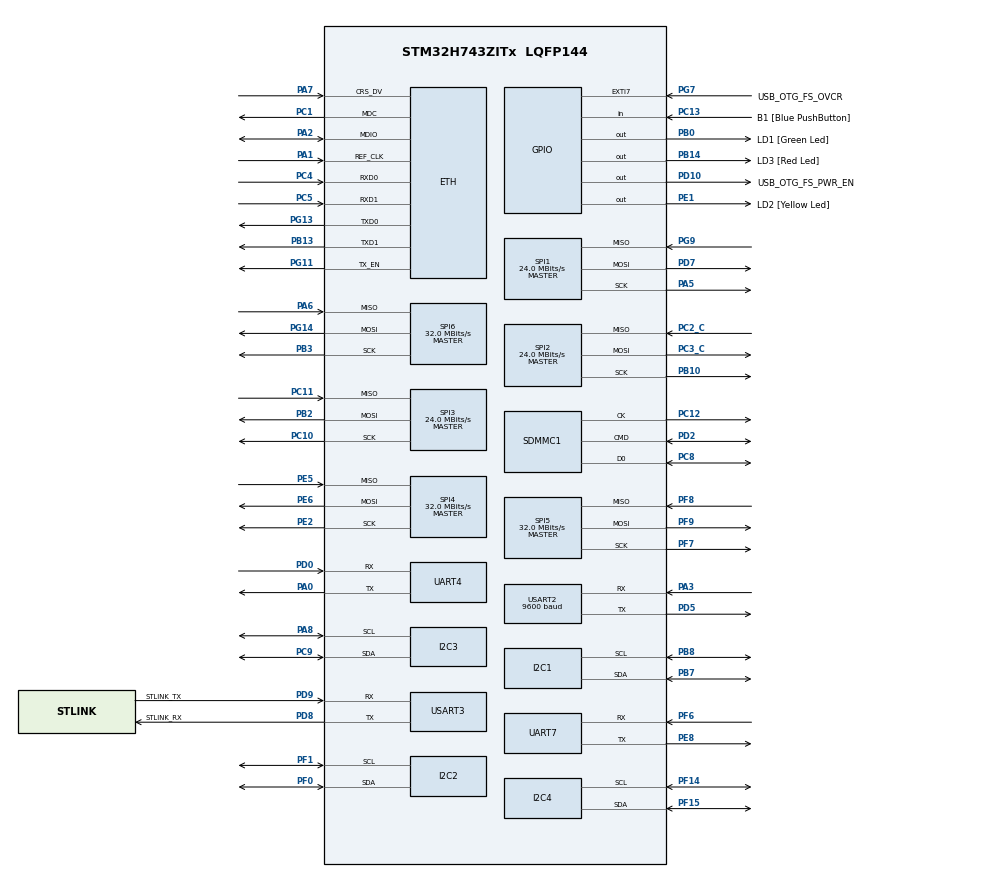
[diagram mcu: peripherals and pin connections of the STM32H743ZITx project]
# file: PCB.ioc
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Dma.Request0=USART2_RX
Dma.USART2_RX.0.Direction=DMA_PERIPH_TO_MEMORY
Dma.USART2_RX.0.EventEnable=DISABLE
Dma.USART2_RX.0.FIFOMode=DMA_FIFOMODE_DISABLE
Dma.USART2_RX.0.Instance=DMA2_Stream0
Dma.USART2_RX.0.MemDataAlignment=DMA_MDATAALIGN_BYTE
Dma.USART2_RX.0.MemInc=DMA_MINC_ENABLE
Dma.USART2_RX.0.Mode=DMA_CIRCULAR
Dma.USART2_RX.0.PeriphDataAlignment=DMA_PDATAALIGN_BYTE
Dma.USART2_RX.0.PeriphInc=DMA_PINC_DISABLE
Dma.USART2_RX.0.Polarity=HAL_DMAMUX_REQ_GEN_RISING
Dma.USART2_RX.0.Priority=DMA_PRIORITY_LOW
Dma.USART2_RX.0.RequestNumber=1
Dma.USART2_RX.0.SignalID=NONE
Dma.USART2_RX.0.SyncEnable=DISABLE
Dma.USART2_RX.0.SyncPolarity=HAL_DMAMUX_SYNC_NO_EVENT
Dma.USART2_RX.0.SyncRequestNumber=1
Dma.USART2_RX.0.SyncSignalID=NONE
ETH.MediaInterface=HAL_ETH_RMII_MODE
Mcu.Family=STM32H7
Mcu.Name=STM32H743ZITx
Mcu.Package=LQFP144
NVIC.DMA2_Stream0_IRQn=true\:0\:0\:false\:false\:true\:false\:true\:true
NVIC.PriorityGroup=NVIC_PRIORITYGROUP_4
NVIC.USART2_IRQn=true\:0\:0\:false\:false\:true\:true\:true\:true
PA0.Mode=Asynchronous
PA0.Signal=UART4_TX
PA1.Mode=RMII
PA1.Signal=ETH_REF_CLK
PA11.Signal=USB_OTG_FS_DM
PA12.Signal=USB_OTG_FS_DP
PA2.Mode=RMII
PA2.Signal=ETH_MDIO
PA3.Mode=Asynchronous
PA3.Signal=USART2_RX
PA5.Mode=Full_Duplex_Master
PA5.Signal=SPI1_SCK
PA6.Mode=Full_Duplex_Master
PA6.Signal=SPI6_MISO
PA7.Mode=RMII
PA7.Signal=ETH_CRS_DV
PA8.Mode=I2C
PA8.Signal=I2C3_SCL
PA9.Signal=I2C3_SMBA
PB0.GPIO_Label=LD1 [Green Led]
PB0.Signal=GPIO_Output
PB10.Mode=Full_Duplex_Master
PB10.Signal=SPI2_SCK
PB13.Mode=RMII
PB13.Signal=ETH_TXD1
PB14.GPIO_Label=LD3 [Red Led]
PB14.Signal=GPIO_Output
PB2.Mode=Full_Duplex_Master
PB2.Signal=SPI3_MOSI
PB3\ (JTDO/TRACESWO).Mode=Full_Duplex_Master
PB3\ (JTDO/TRACESWO).Signal=SPI6_SCK
PB7.Mode=I2C
PB7.Signal=I2C1_SDA
PB8.Mode=I2C
PB8.Signal=I2C1_SCL
PC1.Mode=RMII
PC1.Signal=ETH_MDC
PC10.Mode=Full_Duplex_Master
PC10.Signal=SPI3_SCK
PC11.Mode=Full_Duplex_Master
PC11.Signal=SPI3_MISO
PC12.Mode=SD_1_bit
PC12.Signal=SDMMC1_CK
PC13.GPIO_Label=B1 [Blue PushButton]
PC13.Signal=GPIO_Input
PC14-OSC32_IN\ (OSC32_IN).Mode=LSE-External-Oscillator
PC14-OSC32_IN\ (OSC32_IN).Signal=RCC_OSC32_IN
PC15-OSC32_OUT\ (OSC32_OUT).Mode=LSE-External-Oscillator
PC15-OSC32_OUT\ (OSC32_OUT).Signal=RCC_OSC32_OUT
PC2_C.Mode=Full_Duplex_Master
PC2_C.Signal=SPI2_MISO
PC3_C.Mode=Full_Duplex_Master
PC3_C.Signal=SPI2_MOSI
PC4.Mode=RMII
PC4.Signal=ETH_RXD0
PC5.Mode=RMII
PC5.Signal=ETH_RXD1
PC8.Mode=SD_1_bit
PC8.Signal=SDMMC1_D0
PC9.Mode=I2C
PC9.Signal=I2C3_SDA
PD0.Mode=Asynchronous
PD0.Signal=UART4_RX
PD10.GPIO_Label=USB_OTG_FS_PWR_EN
PD10.Signal=GPIO_Output
PD2.Mode=SD_1_bit
PD2.Signal=SDMMC1_CMD
PD5.Mode=Asynchronous
PD5.Signal=USART2_TX
PD7.Mode=Full_Duplex_Master
PD7.Signal=SPI1_MOSI
PD8.GPIO_Label=STLINK_RX
PD8.Mode=Asynchronous
PD8.Signal=USART3_TX
PD9.GPIO_Label=STLINK_TX
PD9.Mode=Asynchronous
PD9.Signal=USART3_RX
PE1.GPIO_Label=LD2 [Yellow Led]
PE1.Signal=GPIO_Output
PE2.Mode=Full_Duplex_Master
PE2.Signal=SPI4_SCK
PE5.Mode=Full_Duplex_Master
PE5.Signal=SPI4_MISO
PE6.Mode=Full_Duplex_Master
PE6.Signal=SPI4_MOSI
PE8.Mode=Asynchronous
PE8.Signal=UART7_TX
PF0.Mode=I2C
PF0.Signal=I2C2_SDA
PF1.Mode=I2C
PF1.Signal=I2C2_SCL
PF14.Mode=I2C
PF14.Signal=I2C4_SCL
PF15.Mode=I2C
PF15.Signal=I2C4_SDA
PF6.Mode=Asynchronous
PF6.Signal=UART7_RX
PF7.Mode=Full_Duplex_Master
PF7.Signal=SPI5_SCK
PF8.Mode=Full_Duplex_Master
PF8.Signal=SPI5_MISO
PF9.Mode=Full_Duplex_Master
PF9.Signal=SPI5_MOSI
PG11.Mode=RMII
PG11.Signal=ETH_TX_EN
PG13.Mode=RMII
PG13.Signal=ETH_TXD0
PG14.Mode=Full_Duplex_Master
PG14.Signal=SPI6_MOSI
PG7.GPIO_Label=USB_OTG_FS_OVCR
PG7.Signal=GPXTI7
PG9.Mode=Full_Duplex_Master
PG9.Signal=SPI1_MISO
PH0-OSC_IN\ (PH0).Mode=HSE-External-Clock-Source
PH0-OSC_IN\ (PH0).Signal=RCC_OSC_IN
PH1-OSC_OUT\ (PH1).Signal=RCC_OSC_OUT
ProjectManager.HeapSize=0x200
ProjectManager.StackSize=0x400
ProjectManager.TargetToolchain=STM32CubeIDE
RCC.ADCFreq_Value=16125000
RCC.APB1Freq_Value=64000000
RCC.APB2Freq_Value=64000000
RCC.APB3Freq_Value=64000000
RCC.APB4Freq_Value=64000000
RCC.CortexFreq_Value=64000000
RCC.DIVM1=1
RCC.DIVN1=24
RCC.DIVQ1=4
RCC.HCLKFreq_Value=64000000
RCC.HSE_VALUE=8000000
RCC.PLLFRACN=0
RCC.PLLSourceVirtual=RCC_PLLSOURCE_HSE
RCC.PWR_Regulator_Voltage_Scale=PWR_REGULATOR_VOLTAGE_SCALE2
RCC.SYSCLKFreq_VALUE=64000000
RCC.USBFreq_Value=48000000
SPI1.CalculateBaudRate=24.0 MBits/s
SPI1.Direction=SPI_DIRECTION_2LINES
SPI1.Mode=SPI_MODE_MASTER
SPI1.VirtualType=VM_MASTER
SPI2.CalculateBaudRate=24.0 MBits/s
SPI2.Direction=SPI_DIRECTION_2LINES
SPI2.Mode=SPI_MODE_MASTER
SPI2.VirtualType=VM_MASTER
SPI3.CalculateBaudRate=24.0 MBits/s
SPI3.Direction=SPI_DIRECTION_2LINES
SPI3.Mode=SPI_MODE_MASTER
SPI3.VirtualType=VM_MASTER
SPI4.CalculateBaudRate=32.0 MBits/s
SPI4.Direction=SPI_DIRECTION_2LINES
SPI4.Mode=SPI_MODE_MASTER
SPI4.VirtualType=VM_MASTER
SPI5.CalculateBaudRate=32.0 MBits/s
SPI5.Direction=SPI_DIRECTION_2LINES
SPI5.Mode=SPI_MODE_MASTER
SPI5.VirtualType=VM_MASTER
SPI6.CalculateBaudRate=32.0 MBits/s
SPI6.Direction=SPI_DIRECTION_2LINES
SPI6.Mode=SPI_MODE_MASTER
SPI6.VirtualType=VM_MASTER
USART2.BaudRate=9600
USART2.VirtualMode-Asynchronous=VM_ASYNC
USART3.VirtualMode-Asynchronous=VM_ASYNC
board=NUCLEO-H743ZI2

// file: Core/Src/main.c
/* USER CODE BEGIN Header */
/**
  ******************************************************************************
  * @file           : main.c
  * @brief          : Main program body
  ******************************************************************************
  * @attention
  *
  * Copyright (c) 2024 STMicroelectronics.
  * All rights reserved.
  *
  * This software is licensed under terms that can be found in the LICENSE file
  * in the root directory of this software component.
  * If no LICENSE file comes with this software, it is provided AS-IS.
  *
  ******************************************************************************
  */
/* USER CODE END Header */
#include "main.h"
#include "string.h"

/* USER CODE BEGIN Includes */
#include "barometer.h"
#include "gps.h"
/* USER CODE END Includes */

#if defined ( __ICCARM__ ) /*!< IAR Compiler */
#pragma location=0x30000000
ETH_DMADescTypeDef  DMARxDscrTab[ETH_RX_DESC_CNT]; /* Ethernet Rx DMA Descriptors */
#pragma location=0x30000200
ETH_DMADescTypeDef  DMATxDscrTab[ETH_TX_DESC_CNT]; /* Ethernet Tx DMA Descriptors */

#elif defined ( __CC_ARM )  /* MDK ARM Compiler */

__attribute__((at(0x30000000))) ETH_DMADescTypeDef  DMARxDscrTab[ETH_RX_DESC_CNT]; /* Ethernet Rx DMA Descriptors */
__attribute__((at(0x30000200))) ETH_DMADescTypeDef  DMATxDscrTab[ETH_TX_DESC_CNT]; /* Ethernet Tx DMA Descriptors */

#elif defined ( __GNUC__ ) /* GNU Compiler */
ETH_DMADescTypeDef DMARxDscrTab[ETH_RX_DESC_CNT] __attribute__((section(".RxDecripSection"))); /* Ethernet Rx DMA Descriptors */
ETH_DMADescTypeDef DMATxDscrTab[ETH_TX_DESC_CNT] __attribute__((section(".TxDecripSection")));   /* Ethernet Tx DMA Descriptors */

#endif

ETH_TxPacketConfig TxConfig;

ETH_HandleTypeDef heth;

I2C_HandleTypeDef hi2c1;
I2C_HandleTypeDef hi2c2;
I2C_HandleTypeDef hi2c3;
I2C_HandleTypeDef hi2c4;

SD_HandleTypeDef hsd1;

SPI_HandleTypeDef hspi1;
SPI_HandleTypeDef hspi2;
SPI_HandleTypeDef hspi3;
SPI_HandleTypeDef hspi4;
SPI_HandleTypeDef hspi5;
SPI_HandleTypeDef hspi6;

UART_HandleTypeDef huart4;
UART_HandleTypeDef huart7;
UART_HandleTypeDef huart2;
UART_HandleTypeDef huart3;
DMA_HandleTypeDef hdma_usart2_rx;

void SystemClock_Config(void);
static void MX_GPIO_Init(void);
static void MX_DMA_Init(void);
static void MX_I2C1_Init(void);
static void MX_I2C2_Init(void);
static void MX_I2C3_Init(void);
static void MX_I2C4_Init(void);
static void MX_SDMMC1_SD_Init(void);
static void MX_SPI1_Init(void);
static void MX_SPI2_Init(void);
static void MX_SPI3_Init(void);
static void MX_SPI4_Init(void);
static void MX_SPI5_Init(void);
static void MX_SPI6_Init(void);
static void MX_UART4_Init(void);
static void MX_UART7_Init(void);
static void MX_USART2_UART_Init(void);
static void MX_ETH_Init(void);
static void MX_USART3_UART_Init(void);

int main(void)
{

  /* MCU Configuration--------------------------------------------------------*/

  /* Reset of all peripherals, Initializes the Flash interface and the Systick. */
  HAL_Init();

  /* Configure the system clock */
  SystemClock_Config();

  /* Initialize all configured peripherals */
  MX_GPIO_Init();
  MX_DMA_Init();
  MX_I2C1_Init();
  MX_I2C2_Init();
  MX_I2C3_Init();
  MX_I2C4_Init();
  MX_SDMMC1_SD_Init();
  MX_SPI1_Init();
  MX_SPI2_Init();
  MX_SPI3_Init();
  MX_SPI4_Init();
  MX_SPI5_Init();
  MX_SPI6_Init();
  MX_UART4_Init();
  MX_UART7_Init();
  MX_USART2_UART_Init();
  MX_ETH_Init();
  MX_USART3_UART_Init();
  /* USER CODE BEGIN 2 */
  DPS310_Start();
  /* USER CODE END 2 */

  /* Infinite loop */
  while (1)
  {
	  DPS310_Poll();	//3x Baro on I2C1,I2C2, I2C3, outputs on UART2
	  get_location();	//1x GPS on UART2
  }
}

void SystemClock_Config(void)
{
  RCC_OscInitTypeDef RCC_OscInitStruct = {0};
  RCC_ClkInitTypeDef RCC_ClkInitStruct = {0};

  /** Supply configuration update enable
  */
  HAL_PWREx_ConfigSupply(PWR_LDO_SUPPLY);

  /** Configure the main internal regulator output voltage
  */
  __HAL_PWR_VOLTAGESCALING_CONFIG(PWR_REGULATOR_VOLTAGE_SCALE2);

  while(!__HAL_PWR_GET_FLAG(PWR_FLAG_VOSRDY)) {}

  /** Initializes the RCC Oscillators according to the specified parameters
  * in the RCC_OscInitTypeDef structure.
  */
  RCC_OscInitStruct.OscillatorType = RCC_OSCILLATORTYPE_HSI|RCC_OSCILLATORTYPE_HSE;
  RCC_OscInitStruct.HSEState = RCC_HSE_BYPASS;
  RCC_OscInitStruct.HSIState = RCC_HSI_DIV1;
  RCC_OscInitStruct.HSICalibrationValue = RCC_HSICALIBRATION_DEFAULT;
  RCC_OscInitStruct.PLL.PLLState = RCC_PLL_ON;
  RCC_OscInitStruct.PLL.PLLSource = RCC_PLLSOURCE_HSE;
  RCC_OscInitStruct.PLL.PLLM = 1;
  RCC_OscInitStruct.PLL.PLLN = 24;
  RCC_OscInitStruct.PLL.PLLP = 2;
  RCC_OscInitStruct.PLL.PLLQ = 4;
  RCC_OscInitStruct.PLL.PLLR = 2;
  RCC_OscInitStruct.PLL.PLLRGE = RCC_PLL1VCIRANGE_3;
  RCC_OscInitStruct.PLL.PLLVCOSEL = RCC_PLL1VCOWIDE;
  RCC_OscInitStruct.PLL.PLLFRACN = 0;
  if (HAL_RCC_OscConfig(&RCC_OscInitStruct) != HAL_OK)
  {
    Error_Handler();
  }

  /** Initializes the CPU, AHB and APB buses clocks
  */
  RCC_ClkInitStruct.ClockType = RCC_CLOCKTYPE_HCLK|RCC_CLOCKTYPE_SYSCLK
                              |RCC_CLOCKTYPE_PCLK1|RCC_CLOCKTYPE_PCLK2
                              |RCC_CLOCKTYPE_D3PCLK1|RCC_CLOCKTYPE_D1PCLK1;
  RCC_ClkInitStruct.SYSCLKSource = RCC_SYSCLKSOURCE_HSI;
  RCC_ClkInitStruct.SYSCLKDivider = RCC_SYSCLK_DIV1;
  RCC_ClkInitStruct.AHBCLKDivider = RCC_HCLK_DIV1;
  RCC_ClkInitStruct.APB3CLKDivider = RCC_APB3_DIV1;
  RCC_ClkInitStruct.APB1CLKDivider = RCC_APB1_DIV1;
  RCC_ClkInitStruct.APB2CLKDivider = RCC_APB2_DIV1;
  RCC_ClkInitStruct.APB4CLKDivider = RCC_APB4_DIV1;

  if (HAL_RCC_ClockConfig(&RCC_ClkInitStruct, FLASH_LATENCY_1) != HAL_OK)
  {
    Error_Handler();
  }
}

static void MX_ETH_Init(void)
{

   static uint8_t MACAddr[6];

  heth.Instance = ETH;
  MACAddr[0] = 0x00;
  MACAddr[1] = 0x80;
  MACAddr[2] = 0xE1;
  MACAddr[3] = 0x00;
  MACAddr[4] = 0x00;
  MACAddr[5] = 0x00;
  heth.Init.MACAddr = &MACAddr[0];
  heth.Init.MediaInterface = HAL_ETH_RMII_MODE;
  heth.Init.TxDesc = DMATxDscrTab;
  heth.Init.RxDesc = DMARxDscrTab;
  heth.Init.RxBuffLen = 1524;

  if (HAL_ETH_Init(&heth) != HAL_OK)
  {
    Error_Handler();
  }

  memset(&TxConfig, 0 , sizeof(ETH_TxPacketConfig));
  TxConfig.Attributes = ETH_TX_PACKETS_FEATURES_CSUM | ETH_TX_PACKETS_FEATURES_CRCPAD;
  TxConfig.ChecksumCtrl = ETH_CHECKSUM_IPHDR_PAYLOAD_INSERT_PHDR_CALC;
  TxConfig.CRCPadCtrl = ETH_CRC_PAD_INSERT;

}

static void MX_I2C1_Init(void)
{

  hi2c1.Instance = I2C1;
  hi2c1.Init.Timing = 0x10707DBC;
  hi2c1.Init.OwnAddress1 = 0;
  hi2c1.Init.AddressingMode = I2C_ADDRESSINGMODE_7BIT;
  hi2c1.Init.DualAddressMode = I2C_DUALADDRESS_DISABLE;
  hi2c1.Init.OwnAddress2 = 0;
  hi2c1.Init.OwnAddress2Masks = I2C_OA2_NOMASK;
  hi2c1.Init.GeneralCallMode = I2C_GENERALCALL_DISABLE;
  hi2c1.Init.NoStretchMode = I2C_NOSTRETCH_DISABLE;
  if (HAL_I2C_Init(&hi2c1) != HAL_OK)
  {
    Error_Handler();
  }

  /** Configure Analogue filter
  */
  if (HAL_I2CEx_ConfigAnalogFilter(&hi2c1, I2C_ANALOGFILTER_ENABLE) != HAL_OK)
  {
    Error_Handler();
  }

  /** Configure Digital filter
  */
  if (HAL_I2CEx_ConfigDigitalFilter(&hi2c1, 0) != HAL_OK)
  {
    Error_Handler();
  }

}

static void MX_I2C2_Init(void)
{

  hi2c2.Instance = I2C2;
  hi2c2.Init.Timing = 0x10707DBC;
  hi2c2.Init.OwnAddress1 = 0;
  hi2c2.Init.AddressingMode = I2C_ADDRESSINGMODE_7BIT;
  hi2c2.Init.DualAddressMode = I2C_DUALADDRESS_DISABLE;
  hi2c2.Init.OwnAddress2 = 0;
  hi2c2.Init.OwnAddress2Masks = I2C_OA2_NOMASK;
  hi2c2.Init.GeneralCallMode = I2C_GENERALCALL_DISABLE;
  hi2c2.Init.NoStretchMode = I2C_NOSTRETCH_DISABLE;
  if (HAL_I2C_Init(&hi2c2) != HAL_OK)
  {
    Error_Handler();
  }

  /** Configure Analogue filter
  */
  if (HAL_I2CEx_ConfigAnalogFilter(&hi2c2, I2C_ANALOGFILTER_ENABLE) != HAL_OK)
  {
    Error_Handler();
  }

  /** Configure Digital filter
  */
  if (HAL_I2CEx_ConfigDigitalFilter(&hi2c2, 0) != HAL_OK)
  {
    Error_Handler();
  }

}

static void MX_I2C3_Init(void)
{

  hi2c3.Instance = I2C3;
  hi2c3.Init.Timing = 0x10707DBC;
  hi2c3.Init.OwnAddress1 = 0;
  hi2c3.Init.AddressingMode = I2C_ADDRESSINGMODE_7BIT;
  hi2c3.Init.DualAddressMode = I2C_DUALADDRESS_DISABLE;
  hi2c3.Init.OwnAddress2 = 0;
  hi2c3.Init.OwnAddress2Masks = I2C_OA2_NOMASK;
  hi2c3.Init.GeneralCallMode = I2C_GENERALCALL_DISABLE;
  hi2c3.Init.NoStretchMode = I2C_NOSTRETCH_DISABLE;
  if (HAL_I2C_Init(&hi2c3) != HAL_OK)
  {
    Error_Handler();
  }

  /** Configure Analogue filter
  */
  if (HAL_I2CEx_ConfigAnalogFilter(&hi2c3, I2C_ANALOGFILTER_ENABLE) != HAL_OK)
  {
    Error_Handler();
  }

  /** Configure Digital filter
  */
  if (HAL_I2CEx_ConfigDigitalFilter(&hi2c3, 0) != HAL_OK)
  {
    Error_Handler();
  }

}

static void MX_I2C4_Init(void)
{

  hi2c4.Instance = I2C4;
  hi2c4.Init.Timing = 0x10707DBC;
  hi2c4.Init.OwnAddress1 = 0;
  hi2c4.Init.AddressingMode = I2C_ADDRESSINGMODE_7BIT;
  hi2c4.Init.DualAddressMode = I2C_DUALADDRESS_DISABLE;
  hi2c4.Init.OwnAddress2 = 0;
  hi2c4.Init.OwnAddress2Masks = I2C_OA2_NOMASK;
  hi2c4.Init.GeneralCallMode = I2C_GENERALCALL_DISABLE;
  hi2c4.Init.NoStretchMode = I2C_NOSTRETCH_DISABLE;
  if (HAL_I2C_Init(&hi2c4) != HAL_OK)
  {
    Error_Handler();
  }

  /** Configure Analogue filter
  */
  if (HAL_I2CEx_ConfigAnalogFilter(&hi2c4, I2C_ANALOGFILTER_ENABLE) != HAL_OK)
  {
    Error_Handler();
  }

  /** Configure Digital filter
  */
  if (HAL_I2CEx_ConfigDigitalFilter(&hi2c4, 0) != HAL_OK)
  {
    Error_Handler();
  }

}

static void MX_SDMMC1_SD_Init(void)
{

  hsd1.Instance = SDMMC1;
  hsd1.Init.ClockEdge = SDMMC_CLOCK_EDGE_RISING;
  hsd1.Init.ClockPowerSave = SDMMC_CLOCK_POWER_SAVE_DISABLE;
  hsd1.Init.BusWide = SDMMC_BUS_WIDE_1B;
  hsd1.Init.HardwareFlowControl = SDMMC_HARDWARE_FLOW_CONTROL_DISABLE;
  hsd1.Init.ClockDiv = 0;
  if (HAL_SD_Init(&hsd1) != HAL_OK)
  {
    Error_Handler();
  }

}

static void MX_SPI1_Init(void)
{

  /* SPI1 parameter configuration*/
  hspi1.Instance = SPI1;
  hspi1.Init.Mode = SPI_MODE_MASTER;
  hspi1.Init.Direction = SPI_DIRECTION_2LINES;
  hspi1.Init.DataSize = SPI_DATASIZE_4BIT;
  hspi1.Init.CLKPolarity = SPI_POLARITY_LOW;
  hspi1.Init.CLKPhase = SPI_PHASE_1EDGE;
  hspi1.Init.NSS = SPI_NSS_SOFT;
  hspi1.Init.BaudRatePrescaler = SPI_BAUDRATEPRESCALER_2;
  hspi1.Init.FirstBit = SPI_FIRSTBIT_MSB;
  hspi1.Init.TIMode = SPI_TIMODE_DISABLE;
  hspi1.Init.CRCCalculation = SPI_CRCCALCULATION_DISABLE;
  hspi1.Init.CRCPolynomial = 0x0;
  hspi1.Init.NSSPMode = SPI_NSS_PULSE_ENABLE;
  hspi1.Init.NSSPolarity = SPI_NSS_POLARITY_LOW;
  hspi1.Init.FifoThreshold = SPI_FIFO_THRESHOLD_01DATA;
  hspi1.Init.TxCRCInitializationPattern = SPI_CRC_INITIALIZATION_ALL_ZERO_PATTERN;
  hspi1.Init.RxCRCInitializationPattern = SPI_CRC_INITIALIZATION_ALL_ZERO_PATTERN;
  hspi1.Init.MasterSSIdleness = SPI_MASTER_SS_IDLENESS_00CYCLE;
  hspi1.Init.MasterInterDataIdleness = SPI_MASTER_INTERDATA_IDLENESS_00CYCLE;
  hspi1.Init.MasterReceiverAutoSusp = SPI_MASTER_RX_AUTOSUSP_DISABLE;
  hspi1.Init.MasterKeepIOState = SPI_MASTER_KEEP_IO_STATE_DISABLE;
  hspi1.Init.IOSwap = SPI_IO_SWAP_DISABLE;
  if (HAL_SPI_Init(&hspi1) != HAL_OK)
  {
    Error_Handler();
  }

}

static void MX_SPI2_Init(void)
{

  /* SPI2 parameter configuration*/
  hspi2.Instance = SPI2;
  hspi2.Init.Mode = SPI_MODE_MASTER;
  hspi2.Init.Direction = SPI_DIRECTION_2LINES;
  hspi2.Init.DataSize = SPI_DATASIZE_4BIT;
  hspi2.Init.CLKPolarity = SPI_POLARITY_LOW;
  hspi2.Init.CLKPhase = SPI_PHASE_1EDGE;
  hspi2.Init.NSS = SPI_NSS_SOFT;
  hspi2.Init.BaudRatePrescaler = SPI_BAUDRATEPRESCALER_2;
  hspi2.Init.FirstBit = SPI_FIRSTBIT_MSB;
  hspi2.Init.TIMode = SPI_TIMODE_DISABLE;
  hspi2.Init.CRCCalculation = SPI_CRCCALCULATION_DISABLE;
  hspi2.Init.CRCPolynomial = 0x0;
  hspi2.Init.NSSPMode = SPI_NSS_PULSE_ENABLE;
  hspi2.Init.NSSPolarity = SPI_NSS_POLARITY_LOW;
  hspi2.Init.FifoThreshold = SPI_FIFO_THRESHOLD_01DATA;
  hspi2.Init.TxCRCInitializationPattern = SPI_CRC_INITIALIZATION_ALL_ZERO_PATTERN;
  hspi2.Init.RxCRCInitializationPattern = SPI_CRC_INITIALIZATION_ALL_ZERO_PATTERN;
  hspi2.Init.MasterSSIdleness = SPI_MASTER_SS_IDLENESS_00CYCLE;
  hspi2.Init.MasterInterDataIdleness = SPI_MASTER_INTERDATA_IDLENESS_00CYCLE;
  hspi2.Init.MasterReceiverAutoSusp = SPI_MASTER_RX_AUTOSUSP_DISABLE;
  hspi2.Init.MasterKeepIOState = SPI_MASTER_KEEP_IO_STATE_DISABLE;
  hspi2.Init.IOSwap = SPI_IO_SWAP_DISABLE;
  if (HAL_SPI_Init(&hspi2) != HAL_OK)
  {
    Error_Handler();
  }

}

static void MX_SPI3_Init(void)
{

  /* SPI3 parameter configuration*/
  hspi3.Instance = SPI3;
  hspi3.Init.Mode = SPI_MODE_MASTER;
  hspi3.Init.Direction = SPI_DIRECTION_2LINES;
  hspi3.Init.DataSize = SPI_DATASIZE_4BIT;
  hspi3.Init.CLKPolarity = SPI_POLARITY_LOW;
  hspi3.Init.CLKPhase = SPI_PHASE_1EDGE;
  hspi3.Init.NSS = SPI_NSS_SOFT;
  hspi3.Init.BaudRatePrescaler = SPI_BAUDRATEPRESCALER_2;
  hspi3.Init.FirstBit = SPI_FIRSTBIT_MSB;
  hspi3.Init.TIMode = SPI_TIMODE_DISABLE;
  hspi3.Init.CRCCalculation = SPI_CRCCALCULATION_DISABLE;
  hspi3.Init.CRCPolynomial = 0x0;
  hspi3.Init.NSSPMode = SPI_NSS_PULSE_ENABLE;
  hspi3.Init.NSSPolarity = SPI_NSS_POLARITY_LOW;
  hspi3.Init.FifoThreshold = SPI_FIFO_THRESHOLD_01DATA;
  hspi3.Init.TxCRCInitializationPattern = SPI_CRC_INITIALIZATION_ALL_ZERO_PATTERN;
  hspi3.Init.RxCRCInitializationPattern = SPI_CRC_INITIALIZATION_ALL_ZERO_PATTERN;
  hspi3.Init.MasterSSIdleness = SPI_MASTER_SS_IDLENESS_00CYCLE;
  hspi3.Init.MasterInterDataIdleness = SPI_MASTER_INTERDATA_IDLENESS_00CYCLE;
  hspi3.Init.MasterReceiverAutoSusp = SPI_MASTER_RX_AUTOSUSP_DISABLE;
  hspi3.Init.MasterKeepIOState = SPI_MASTER_KEEP_IO_STATE_DISABLE;
  hspi3.Init.IOSwap = SPI_IO_SWAP_DISABLE;
  if (HAL_SPI_Init(&hspi3) != HAL_OK)
  {
    Error_Handler();
  }

}

static void MX_SPI4_Init(void)
{

  /* SPI4 parameter configuration*/
  hspi4.Instance = SPI4;
  hspi4.Init.Mode = SPI_MODE_MASTER;
  hspi4.Init.Direction = SPI_DIRECTION_2LINES;
  hspi4.Init.DataSize = SPI_DATASIZE_4BIT;
  hspi4.Init.CLKPolarity = SPI_POLARITY_LOW;
  hspi4.Init.CLKPhase = SPI_PHASE_1EDGE;
  hspi4.Init.NSS = SPI_NSS_SOFT;
  hspi4.Init.BaudRatePrescaler = SPI_BAUDRATEPRESCALER_2;
  hspi4.Init.FirstBit = SPI_FIRSTBIT_MSB;
  hspi4.Init.TIMode = SPI_TIMODE_DISABLE;
  hspi4.Init.CRCCalculation = SPI_CRCCALCULATION_DISABLE;
  hspi4.Init.CRCPolynomial = 0x0;
  hspi4.Init.NSSPMode = SPI_NSS_PULSE_ENABLE;
  hspi4.Init.NSSPolarity = SPI_NSS_POLARITY_LOW;
  hspi4.Init.FifoThreshold = SPI_FIFO_THRESHOLD_01DATA;
  hspi4.Init.TxCRCInitializationPattern = SPI_CRC_INITIALIZATION_ALL_ZERO_PATTERN;
  hspi4.Init.RxCRCInitializationPattern = SPI_CRC_INITIALIZATION_ALL_ZERO_PATTERN;
  hspi4.Init.MasterSSIdleness = SPI_MASTER_SS_IDLENESS_00CYCLE;
  hspi4.Init.MasterInterDataIdleness = SPI_MASTER_INTERDATA_IDLENESS_00CYCLE;
  hspi4.Init.MasterReceiverAutoSusp = SPI_MASTER_RX_AUTOSUSP_DISABLE;
  hspi4.Init.MasterKeepIOState = SPI_MASTER_KEEP_IO_STATE_DISABLE;
  hspi4.Init.IOSwap = SPI_IO_SWAP_DISABLE;
  if (HAL_SPI_Init(&hspi4) != HAL_OK)
  {
    Error_Handler();
  }

}

static void MX_SPI5_Init(void)
{

  /* SPI5 parameter configuration*/
  hspi5.Instance = SPI5;
  hspi5.Init.Mode = SPI_MODE_MASTER;
  hspi5.Init.Direction = SPI_DIRECTION_2LINES;
  hspi5.Init.DataSize = SPI_DATASIZE_4BIT;
  hspi5.Init.CLKPolarity = SPI_POLARITY_LOW;
  hspi5.Init.CLKPhase = SPI_PHASE_1EDGE;
  hspi5.Init.NSS = SPI_NSS_SOFT;
  hspi5.Init.BaudRatePrescaler = SPI_BAUDRATEPRESCALER_2;
  hspi5.Init.FirstBit = SPI_FIRSTBIT_MSB;
  hspi5.Init.TIMode = SPI_TIMODE_DISABLE;
  hspi5.Init.CRCCalculation = SPI_CRCCALCULATION_DISABLE;
  hspi5.Init.CRCPolynomial = 0x0;
  hspi5.Init.NSSPMode = SPI_NSS_PULSE_ENABLE;
  hspi5.Init.NSSPolarity = SPI_NSS_POLARITY_LOW;
  hspi5.Init.FifoThreshold = SPI_FIFO_THRESHOLD_01DATA;
  hspi5.Init.TxCRCInitializationPattern = SPI_CRC_INITIALIZATION_ALL_ZERO_PATTERN;
  hspi5.Init.RxCRCInitializationPattern = SPI_CRC_INITIALIZATION_ALL_ZERO_PATTERN;
  hspi5.Init.MasterSSIdleness = SPI_MASTER_SS_IDLENESS_00CYCLE;
  hspi5.Init.MasterInterDataIdleness = SPI_MASTER_INTERDATA_IDLENESS_00CYCLE;
  hspi5.Init.MasterReceiverAutoSusp = SPI_MASTER_RX_AUTOSUSP_DISABLE;
  hspi5.Init.MasterKeepIOState = SPI_MASTER_KEEP_IO_STATE_DISABLE;
  hspi5.Init.IOSwap = SPI_IO_SWAP_DISABLE;
  if (HAL_SPI_Init(&hspi5) != HAL_OK)
  {
    Error_Handler();
  }

}

static void MX_SPI6_Init(void)
{

  /* SPI6 parameter configuration*/
  hspi6.Instance = SPI6;
  hspi6.Init.Mode = SPI_MODE_MASTER;
  hspi6.Init.Direction = SPI_DIRECTION_2LINES;
  hspi6.Init.DataSize = SPI_DATASIZE_4BIT;
  hspi6.Init.CLKPolarity = SPI_POLARITY_LOW;
  hspi6.Init.CLKPhase = SPI_PHASE_1EDGE;
  hspi6.Init.NSS = SPI_NSS_SOFT;
  hspi6.Init.BaudRatePrescaler = SPI_BAUDRATEPRESCALER_2;
  hspi6.Init.FirstBit = SPI_FIRSTBIT_MSB;
  hspi6.Init.TIMode = SPI_TIMODE_DISABLE;
  hspi6.Init.CRCCalculation = SPI_CRCCALCULATION_DISABLE;
  hspi6.Init.CRCPolynomial = 0x0;
  hspi6.Init.NSSPMode = SPI_NSS_PULSE_ENABLE;
  hspi6.Init.NSSPolarity = SPI_NSS_POLARITY_LOW;
  hspi6.Init.FifoThreshold = SPI_FIFO_THRESHOLD_01DATA;
  hspi6.Init.TxCRCInitializationPattern = SPI_CRC_INITIALIZATION_ALL_ZERO_PATTERN;
  hspi6.Init.RxCRCInitializationPattern = SPI_CRC_INITIALIZATION_ALL_ZERO_PATTERN;
  hspi6.Init.MasterSSIdleness = SPI_MASTER_SS_IDLENESS_00CYCLE;
  hspi6.Init.MasterInterDataIdleness = SPI_MASTER_INTERDATA_IDLENESS_00CYCLE;
  hspi6.Init.MasterReceiverAutoSusp = SPI_MASTER_RX_AUTOSUSP_DISABLE;
  hspi6.Init.MasterKeepIOState = SPI_MASTER_KEEP_IO_STATE_DISABLE;
  hspi6.Init.IOSwap = SPI_IO_SWAP_DISABLE;
  if (HAL_SPI_Init(&hspi6) != HAL_OK)
  {
    Error_Handler();
  }

}

static void MX_UART4_Init(void)
{

  huart4.Instance = UART4;
  huart4.Init.BaudRate = 115200;
  huart4.Init.WordLength = UART_WORDLENGTH_8B;
  huart4.Init.StopBits = UART_STOPBITS_1;
  huart4.Init.Parity = UART_PARITY_NONE;
  huart4.Init.Mode = UART_MODE_TX_RX;
  huart4.Init.HwFlowCtl = UART_HWCONTROL_NONE;
  huart4.Init.OverSampling = UART_OVERSAMPLING_16;
  huart4.Init.OneBitSampling = UART_ONE_BIT_SAMPLE_DISABLE;
  huart4.Init.ClockPrescaler = UART_PRESCALER_DIV1;
  huart4.AdvancedInit.AdvFeatureInit = UART_ADVFEATURE_NO_INIT;
  if (HAL_UART_Init(&huart4) != HAL_OK)
  {
    Error_Handler();
  }
  if (HAL_UARTEx_SetTxFifoThreshold(&huart4, UART_TXFIFO_THRESHOLD_1_8) != HAL_OK)
  {
    Error_Handler();
  }
  if (HAL_UARTEx_SetRxFifoThreshold(&huart4, UART_RXFIFO_THRESHOLD_1_8) != HAL_OK)
  {
    Error_Handler();
  }
  if (HAL_UARTEx_DisableFifoMode(&huart4) != HAL_OK)
  {
    Error_Handler();
  }

}

static void MX_UART7_Init(void)
{

  huart7.Instance = UART7;
  huart7.Init.BaudRate = 115200;
  huart7.Init.WordLength = UART_WORDLENGTH_8B;
  huart7.Init.StopBits = UART_STOPBITS_1;
  huart7.Init.Parity = UART_PARITY_NONE;
  huart7.Init.Mode = UART_MODE_TX_RX;
  huart7.Init.HwFlowCtl = UART_HWCONTROL_NONE;
  huart7.Init.OverSampling = UART_OVERSAMPLING_16;
  huart7.Init.OneBitSampling = UART_ONE_BIT_SAMPLE_DISABLE;
  huart7.Init.ClockPrescaler = UART_PRESCALER_DIV1;
  huart7.AdvancedInit.AdvFeatureInit = UART_ADVFEATURE_NO_INIT;
  if (HAL_UART_Init(&huart7) != HAL_OK)
  {
    Error_Handler();
  }
  if (HAL_UARTEx_SetTxFifoThreshold(&huart7, UART_TXFIFO_THRESHOLD_1_8) != HAL_OK)
  {
    Error_Handler();
  }
  if (HAL_UARTEx_SetRxFifoThreshold(&huart7, UART_RXFIFO_THRESHOLD_1_8) != HAL_OK)
  {
    Error_Handler();
  }
  if (HAL_UARTEx_DisableFifoMode(&huart7) != HAL_OK)
  {
    Error_Handler();
  }

}

static void MX_USART2_UART_Init(void)
{

  huart2.Instance = USART2;
  huart2.Init.BaudRate = 9600;
  huart2.Init.WordLength = UART_WORDLENGTH_8B;
  huart2.Init.StopBits = UART_STOPBITS_1;
  huart2.Init.Parity = UART_PARITY_NONE;
  huart2.Init.Mode = UART_MODE_TX_RX;
  huart2.Init.HwFlowCtl = UART_HWCONTROL_NONE;
  huart2.Init.OverSampling = UART_OVERSAMPLING_16;
  huart2.Init.OneBitSampling = UART_ONE_BIT_SAMPLE_DISABLE;
  huart2.Init.ClockPrescaler = UART_PRESCALER_DIV1;
  huart2.AdvancedInit.AdvFeatureInit = UART_ADVFEATURE_NO_INIT;
  if (HAL_UART_Init(&huart2) != HAL_OK)
  {
    Error_Handler();
  }
  if (HAL_UARTEx_SetTxFifoThreshold(&huart2, UART_TXFIFO_THRESHOLD_1_8) != HAL_OK)
  {
    Error_Handler();
  }
  if (HAL_UARTEx_SetRxFifoThreshold(&huart2, UART_RXFIFO_THRESHOLD_1_8) != HAL_OK)
  {
    Error_Handler();
  }
  if (HAL_UARTEx_DisableFifoMode(&huart2) != HAL_OK)
  {
    Error_Handler();
  }

}

static void MX_USART3_UART_Init(void)
{

  huart3.Instance = USART3;
  huart3.Init.BaudRate = 115200;
  huart3.Init.WordLength = UART_WORDLENGTH_8B;
  huart3.Init.StopBits = UART_STOPBITS_1;
  huart3.Init.Parity = UART_PARITY_NONE;
  huart3.Init.Mode = UART_MODE_TX_RX;
  huart3.Init.HwFlowCtl = UART_HWCONTROL_NONE;
  huart3.Init.OverSampling = UART_OVERSAMPLING_16;
  huart3.Init.OneBitSampling = UART_ONE_BIT_SAMPLE_DISABLE;
  huart3.Init.ClockPrescaler = UART_PRESCALER_DIV1;
  huart3.AdvancedInit.AdvFeatureInit = UART_ADVFEATURE_NO_INIT;
  if (HAL_UART_Init(&huart3) != HAL_OK)
  {
    Error_Handler();
  }
  if (HAL_UARTEx_SetTxFifoThreshold(&huart3, UART_TXFIFO_THRESHOLD_1_8) != HAL_OK)
  {
    Error_Handler();
  }
  if (HAL_UARTEx_SetRxFifoThreshold(&huart3, UART_RXFIFO_THRESHOLD_1_8) != HAL_OK)
  {
    Error_Handler();
  }
  if (HAL_UARTEx_DisableFifoMode(&huart3) != HAL_OK)
  {
    Error_Handler();
  }

}

static void MX_DMA_Init(void)
{

  /* DMA controller clock enable */
  __HAL_RCC_DMA2_CLK_ENABLE();

  /* DMA interrupt init */
  /* DMA2_Stream0_IRQn interrupt configuration */
  HAL_NVIC_SetPriority(DMA2_Stream0_IRQn, 0, 0);
  HAL_NVIC_EnableIRQ(DMA2_Stream0_IRQn);

}

static void MX_GPIO_Init(void)
{
  GPIO_InitTypeDef GPIO_InitStruct = {0};

  /* GPIO Ports Clock Enable */
  __HAL_RCC_GPIOE_CLK_ENABLE();
  __HAL_RCC_GPIOC_CLK_ENABLE();
  __HAL_RCC_GPIOF_CLK_ENABLE();
  __HAL_RCC_GPIOH_CLK_ENABLE();
  __HAL_RCC_GPIOA_CLK_ENABLE();
  __HAL_RCC_GPIOB_CLK_ENABLE();
  __HAL_RCC_GPIOD_CLK_ENABLE();
  __HAL_RCC_GPIOG_CLK_ENABLE();

  /*Configure GPIO pin Output Level */
  HAL_GPIO_WritePin(GPIOB, LD1_Pin|LD3_Pin, GPIO_PIN_RESET);

  /*Configure GPIO pin Output Level */
  HAL_GPIO_WritePin(USB_OTG_FS_PWR_EN_GPIO_Port, USB_OTG_FS_PWR_EN_Pin, GPIO_PIN_RESET);

  /*Configure GPIO pin Output Level */
  HAL_GPIO_WritePin(LD2_GPIO_Port, LD2_Pin, GPIO_PIN_RESET);

  /*Configure GPIO pin : B1_Pin */
  GPIO_InitStruct.Pin = B1_Pin;
  GPIO_InitStruct.Mode = GPIO_MODE_INPUT;
  GPIO_InitStruct.Pull = GPIO_NOPULL;
  HAL_GPIO_Init(B1_GPIO_Port, &GPIO_InitStruct);

  /*Configure GPIO pins : LD1_Pin LD3_Pin */
  GPIO_InitStruct.Pin = LD1_Pin|LD3_Pin;
  GPIO_InitStruct.Mode = GPIO_MODE_OUTPUT_PP;
  GPIO_InitStruct.Pull = GPIO_NOPULL;
  GPIO_InitStruct.Speed = GPIO_SPEED_FREQ_LOW;
  HAL_GPIO_Init(GPIOB, &GPIO_InitStruct);

  /*Configure GPIO pin : USB_OTG_FS_PWR_EN_Pin */
  GPIO_InitStruct.Pin = USB_OTG_FS_PWR_EN_Pin;
  GPIO_InitStruct.Mode = GPIO_MODE_OUTPUT_PP;
  GPIO_InitStruct.Pull = GPIO_NOPULL;
  GPIO_InitStruct.Speed = GPIO_SPEED_FREQ_LOW;
  HAL_GPIO_Init(USB_OTG_FS_PWR_EN_GPIO_Port, &GPIO_InitStruct);

  /*Configure GPIO pin : USB_OTG_FS_OVCR_Pin */
  GPIO_InitStruct.Pin = USB_OTG_FS_OVCR_Pin;
  GPIO_InitStruct.Mode = GPIO_MODE_IT_RISING;
  GPIO_InitStruct.Pull = GPIO_NOPULL;
  HAL_GPIO_Init(USB_OTG_FS_OVCR_GPIO_Port, &GPIO_InitStruct);

  /*Configure GPIO pins : PA11 PA12 */
  GPIO_InitStruct.Pin = GPIO_PIN_11|GPIO_PIN_12;
  GPIO_InitStruct.Mode = GPIO_MODE_AF_PP;
  GPIO_InitStruct.Pull = GPIO_NOPULL;
  GPIO_InitStruct.Speed = GPIO_SPEED_FREQ_LOW;
  GPIO_InitStruct.Alternate = GPIO_AF10_OTG1_FS;
  HAL_GPIO_Init(GPIOA, &GPIO_InitStruct);

  /*Configure GPIO pin : LD2_Pin */
  GPIO_InitStruct.Pin = LD2_Pin;
  GPIO_InitStruct.Mode = GPIO_MODE_OUTPUT_PP;
  GPIO_InitStruct.Pull = GPIO_NOPULL;
  GPIO_InitStruct.Speed = GPIO_SPEED_FREQ_LOW;
  HAL_GPIO_Init(LD2_GPIO_Port, &GPIO_InitStruct);

}

void Error_Handler(void)
{
  __disable_irq();
  while (1)
  {
  }
}
